# cxd5602 register map
Vendor: Sony Semiconductor Solutions; Series: CXD56xx; File version: 1.0
CPU: CM4 r0p1, little endian, MPU, FPU, 3 interrupt priority bits, 144 interrupts
Registers are 32-bit, read-write, reset 0x0 unless marked. A register's access mark holds for its fields unless they carry their own. Offsets are from the block's base; [hi:lo] are bit positions; {n}, {i} and the like mark numbered series; 'fields as' and 'values as' point back to an identical list.

## CPU_FIFO — CPU FIFO Control
Base 0x4600C400
0x00 FIF_PUSH_FULL ro — TX buffer is full (=1)
  [0] FULL_FLAG — TX buffer is full
    0=not full; 1=full
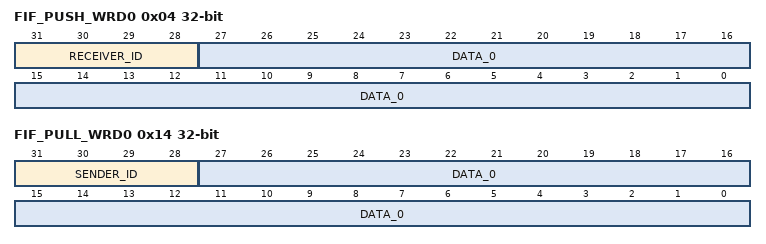
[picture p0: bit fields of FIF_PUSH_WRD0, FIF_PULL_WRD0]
0x04 FIF_PUSH_WRD0 — TX data word 0
  [31:28] RECEIVER_ID — Target ID
  [27:0] DATA_0 — TX data word 0
0x08 FIF_PUSH_WRD1 — TX data word 1
0x0C FIF_PUSH_CMP wo — TX data write complete
  [0] PUSH_CMP
    0=don't care; 1=complete
0x10 FIF_PULL_EMP ro — RX buffer is empty (=1)
  [0] EMPTY_FLAG — RX buffer is empty
    0=not empty; 1=empty
0x14 FIF_PULL_WRD0 — RX data word 0
  [31:28] SENDER_ID
  [27:0] DATA_0 — RX data word 0
0x18 FIF_PULL_WRD1 — RX data word 1
0x1C FIF_PULL_CMP wo — RX data read complete
  [0] PULL_CMP
    0=don't care; 1=complete

## DMAC1 — DMA controller (ADMAC)
Base 0x02020000
0x00 DMACIntStatus ro
  [7:0] IntStatus — Status of the DMA interrupts after masking
0x04 DMACIntTCStatus ro
  [7:0] IntTCStatus — Interrupt terminal count request status
0x08 DMACIntTCClear wo
  [7:0] IntTCClear — Terminal count request clear
0x0C DMACIntErrorStatus ro
  [7:0] IntErrorStatus — Interrupt error status
0x10 DMACIntErrClr wo
  [7:0] IntErrClr — Interrupt error clear
0x14 DMACRawIntTCStatus ro
  [7:0] RawIntTCStatus — Status of the terminal count interrupt prior to masking
0x18 DMACRawIntErrorStatus ro
  [7:0] RawIntErrorStatus — Status of the error interrupt prior to masking
0x1C DMACEnbldChns ro
  [7:0] EnabledChannels — Channel enable status
0x20 DMACSoftBReq
  [15:0] SoftBReq — Software burst request
0x24 DMACSoftSReq
  [15:0] SoftSReq — Software single request
0x28 DMACSoftLBReq
  [15:0] SoftLBReq — Software last burst request
0x2C DMACSoftLSReq
  [15:0] SoftLSReq — Software last single request
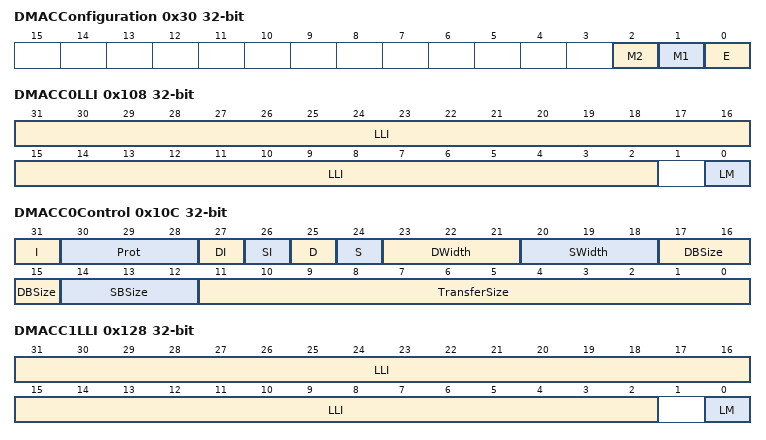
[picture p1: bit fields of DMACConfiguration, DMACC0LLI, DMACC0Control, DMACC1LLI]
0x30 DMACConfiguration
  [2] M2 — AHB Master 2 endianess configuration
    0=LE (Little-endian mode); 1=BE (Big-endian mode)
  [1] M1 — AHB Master 1 endianess configuration
    0=LE (Little-endian mode); 1=BE (Big-endian mode)
  [0] E — DMAC enable
    0=disabled; 1=enabled
0x34 DMACSync reset 0xFFFF
  [15:0] DMACSync — DMA synchronization logic for DMA request signals enabled or disabled
0x100 DMACC0SrcAddr
  [31:0] SrcAddr — DMA source address
0x104 DMACC0DestAddr
  [31:0] DestAddr — DMA destination address
0x108 DMACC0LLI
  [31:2] LLI — Linked list item
  [0] LM — AHB master select for loading the next LLI
    0=AHB1 (AHB Master 1); 1=AHB2 (AHB Master 2)
0x10C DMACC0Control
  [31] I — Terminal count interrupt enable
    0=disabled; 1=enabled
  [30:28] Prot — Protection
  [27] DI — Destination increment
    0=disabled; 1=enabled
  [26] SI — Source increment
    0=disabled; 1=enabled
  [25] D — Destination AHB master select
    0=AHB1 (AHB Master 1); 1=AHB2 (AHB Master 2)
  [24] S — Source AHB master select
    0=AHB1 (AHB Master 1); 1=AHB2 (AHB Master 2)
  [23:21] DWidth — Destination transfer width
    0=Byte, 8-bit; 1=Halfword, 16-bit; 2=Word, 32-bit
  [20:18] SWidth — Source transfer width
    0=Byte, 8-bit; 1=Halfword, 16-bit; 2=Word, 32-bit
  [17:15] DBSize — Destination burst size
    0=1byte; 1=4bytes; 2=8bytes; 3=16bytes; 4=32bytes; 5=64bytes; 6=128bytes; 7=256bytes
  [14:12] SBSize — Source burst size
    values as DBSize
  [11:0] TransferSize
0x110 DMACC0Configuration
0x120 DMACC1SrcAddr
  [31:0] SrcAddr — DMA source address
0x124 DMACC1DestAddr
  [31:0] DestAddr — DMA destination address
0x128 DMACC1LLI
  fields as DMACC0LLI
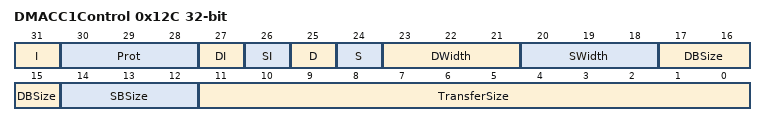
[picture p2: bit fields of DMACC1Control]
0x12C DMACC1Control
  fields as DMACC0Control
0x130 DMACC1Configuration

## DMAC3 — DMA controller (IDMAC)
Base 0x02102000
0x00 DMACIntStatus ro
  [7:0] IntStatus — Status of the DMA interrupts after masking
0x04 DMACIntTCStatus ro
  [7:0] IntTCStatus — Interrupt terminal count request status
0x08 DMACIntTCClear wo
  [7:0] IntTCClear — Terminal count request clear
0x0C DMACIntErrorStatus ro
  [7:0] IntErrorStatus — Interrupt error status
0x10 DMACIntErrClr wo
  [7:0] IntErrClr — Interrupt error clear
0x14 DMACRawIntTCStatus ro
  [7:0] RawIntTCStatus — Status of the terminal count interrupt prior to masking
0x18 DMACRawIntErrorStatus ro
  [7:0] RawIntErrorStatus — Status of the error interrupt prior to masking
0x1C DMACEnbldChns ro
  [7:0] EnabledChannels — Channel enable status
0x20 DMACSoftBReq
  [15:0] SoftBReq — Software burst request
0x24 DMACSoftSReq
  [15:0] SoftSReq — Software single request
0x28 DMACSoftLBReq
  [15:0] SoftLBReq — Software last burst request
0x2C DMACSoftLSReq
  [15:0] SoftLSReq — Software last single request
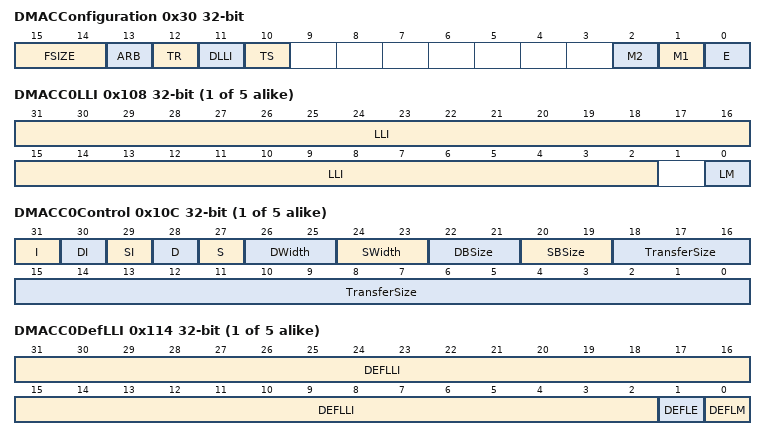
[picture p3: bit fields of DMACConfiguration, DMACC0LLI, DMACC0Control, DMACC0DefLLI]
0x30 DMACConfiguration
  [15:14] FSIZE ro — Transfer Size Extended
    0=16 bytes; 1=32 bytes; 2=64 bytes; 3=128 bytes
  [13] ARB ro — DMAC Arbitration logic
    0=static; 1=roundrobin
  [12] TR ro — Trigger function enabled
    0=disabled; 1=enabled
  [11] DLLI ro — Default LLI enabled
    0=disabled; 1=enabled
  [10] TS ro — Transfer Size Extended
    0=noextended (Not extended); 1=extended
  [2] M2 — AHB Master 2 endianess configuration
    0=LE (Little-endian mode); 1=BE (Big-endian mode)
  [1] M1 — AHB Master 1 endianess configuration
    0=LE (Little-endian mode); 1=BE (Big-endian mode)
  [0] E — DMAC enable
    0=disabled; 1=enabled
0x34 DMACSync reset 0xFFFF
  [15:0] DMACSync — DMA synchronization logic for DMA request signals enabled or disabled
0x38 DMACSREQMask reset 0xFFFF
  [15:0] DMACSREQMask — Mask SREQ signals between DMAC and peripherals
{0x100+0x20*i} DMACC{i}SrcAddr (i=0..4)
  [31:0] SrcAddr — DMA source address
{0x104+0x20*i} DMACC{i}DestAddr (i=0..4)
  [31:0] DestAddr — DMA destination address
{0x108+0x20*i} DMACC{i}LLI (i=0..4)
  [31:2] LLI — Linked list item
  [0] LM — AHB master select for loading the next LLI
    0=AHB1 (AHB Master 1); 1=AHB2 (AHB Master 2)
{0x10C+0x20*i} DMACC{i}Control (i=0..4)
  [31] I — Terminal count interrupt enable
    0=disabled; 1=enabled
  [30] DI — Destination increment
    0=disabled; 1=enabled
  [29] SI — Source increment
    0=disabled; 1=enabled
  [28] D — Destination AHB master select
    0=AHB1 (AHB Master 1); 1=AHB2 (AHB Master 2)
  [27] S — Source AHB master select
    0=AHB1 (AHB Master 1); 1=AHB2 (AHB Master 2)
  [26:25] DWidth — Destination transfer width
    0=Byte, 8-bit; 1=Halfword, 16-bit; 2=Word, 32-bit
  [24:23] SWidth — Source transfer width
    0=Byte, 8-bit; 1=Halfword, 16-bit; 2=Word, 32-bit
  [22:21] DBSize — Destination burst size
    0=1byte; 1=4bytes; 2=8bytes; 3=16bytes
  [20:19] SBSize — Source burst size
    0=1byte; 1=4bytes; 2=8bytes; 3=16bytes
  [18:0] TransferSize
{0x110+0x20*i} DMACC{i}Configuration (i=0..4)
{0x114+0x20*i} DMACC{i}DefLLI (i=0..4)
  [31:2] DEFLLI
  [1] DEFLE — Enable Default LLI
    0=disabled; 1=enabled
  [0] DEFLM — Bus master select
    0=AHB1 (AHB Master 1); 1=AHB2 (AHB Master 2)
